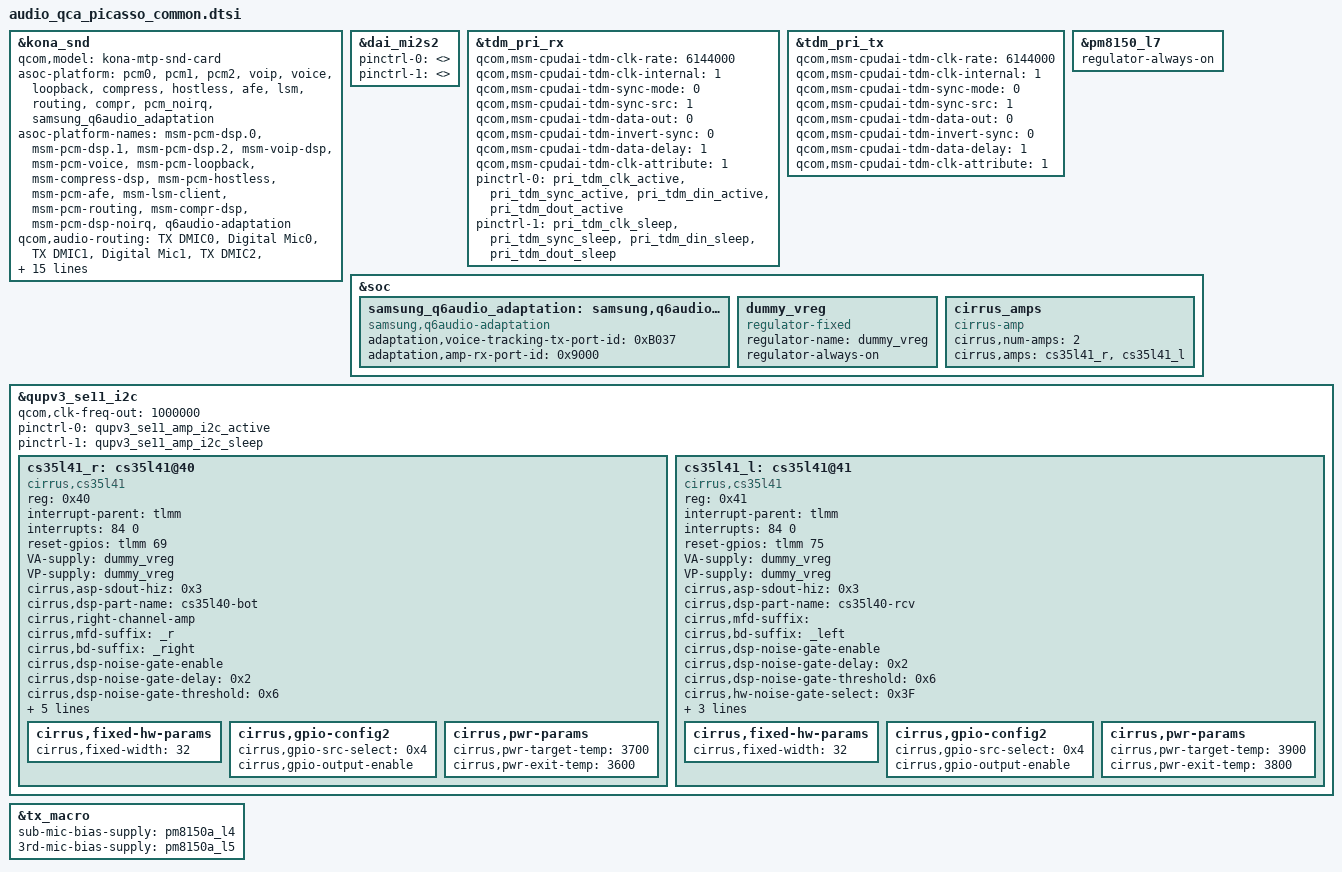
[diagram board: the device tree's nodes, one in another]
/* Copyright (c) 2018, The Linux Foundation. All rights reserved.
 *
 * This program is free software; you can redistribute it and/or modify
 * it under the terms of the GNU General Public License version 2 and
 * only version 2 as published by the Free Software Foundation.
 *
 * This program is distributed in the hope that it will be useful,
 * but WITHOUT ANY WARRANTY; without even the implied warranty of
 * MERCHANTABILITY or FITNESS FOR A PARTICULAR PURPOSE.  See the
 * GNU General Public License for more details.
 */

&kona_snd {
	qcom,model = "kona-mtp-snd-card";

	asoc-platform = <&pcm0>, <&pcm1>, <&pcm2>, <&voip>, <&voice>,
		<&loopback>, <&compress>, <&hostless>,
		<&afe>, <&lsm>, <&routing>, <&compr>,
		<&pcm_noirq>, <&samsung_q6audio_adaptation>;
	asoc-platform-names = "msm-pcm-dsp.0", "msm-pcm-dsp.1",
		"msm-pcm-dsp.2", "msm-voip-dsp",
		"msm-pcm-voice", "msm-pcm-loopback",
		"msm-compress-dsp", "msm-pcm-hostless",
		"msm-pcm-afe", "msm-lsm-client",
		"msm-pcm-routing", "msm-compr-dsp",
		"msm-pcm-dsp-noirq", "q6audio-adaptation";
	qcom,audio-routing =
		"TX DMIC0", "Digital Mic0",
		"TX DMIC1", "Digital Mic1",
		"TX DMIC2", "MIC BIAS External1",
		"MIC BIAS External1", "Digital Mic2",
		"TX DMIC3", "Digital Mic3",
		"TX DMIC4", "MIC BIAS External2",
		"MIC BIAS External2", "Digital Mic4",
		"TX DMIC5", "Digital Mic5",
		"VA DMIC0", "Digital Mic0",
		"VA DMIC1", "Digital Mic1",
		"VA DMIC2", "Digital Mic2",
		"VA DMIC3", "Digital Mic3",
		"VA DMIC4", "Digital Mic4",
		"VA DMIC5", "Digital Mic5",
		"L SPK", "Left AMP SPK",
		"R SPK", "Right AMP SPK";
	qcom,msm-mbhc-hphl-swh = <0>;
	qcom,msm-mbhc-gnd-swh = <0>;
	qcom,wsa-max-devs = <0>;
	qcom,codec-max-aux-devs = <0>;
	fsa4480-i2c-handle = <>;
};

&dai_mi2s2 {
	pinctrl-0 = <>;
	pinctrl-1 = <>;
};

&tdm_pri_rx {
	qcom,msm-cpudai-tdm-clk-rate = <6144000>;
	qcom,msm-cpudai-tdm-clk-internal = <1>;
	qcom,msm-cpudai-tdm-sync-mode = <0>;
	qcom,msm-cpudai-tdm-sync-src = <1>;
	qcom,msm-cpudai-tdm-data-out = <0>;
	qcom,msm-cpudai-tdm-invert-sync = <0>;
	qcom,msm-cpudai-tdm-data-delay = <1>;
	qcom,msm-cpudai-tdm-clk-attribute = /bits/ 16 <1>;

	pinctrl-names = "default", "sleep";
	pinctrl-0 = <&pri_tdm_clk_active &pri_tdm_sync_active
		    &pri_tdm_din_active &pri_tdm_dout_active>;
	pinctrl-1 = <&pri_tdm_clk_sleep &pri_tdm_sync_sleep
			&pri_tdm_din_sleep &pri_tdm_dout_sleep>;
};
&tdm_pri_tx {
	qcom,msm-cpudai-tdm-clk-rate = <6144000>;
	qcom,msm-cpudai-tdm-clk-internal = <1>;
	qcom,msm-cpudai-tdm-sync-mode = <0>;
	qcom,msm-cpudai-tdm-sync-src = <1>;
	qcom,msm-cpudai-tdm-data-out = <0>;
	qcom,msm-cpudai-tdm-invert-sync = <0>;
	qcom,msm-cpudai-tdm-data-delay = <1>;
	qcom,msm-cpudai-tdm-clk-attribute = /bits/ 16 <1>;
};

&pm8150_l7 {
	regulator-always-on;
};

&soc {
	samsung_q6audio_adaptation: samsung,q6audio-adaptation {
		compatible = "samsung,q6audio-adaptation";
		adaptation,voice-tracking-tx-port-id = <0xB037>;
		adaptation,amp-rx-port-id = <0x9000>;
	};

	dummy_vreg: dummy_vreg {
		compatible = "regulator-fixed";
		status = "ok";
		regulator-name = "dummy_vreg";
		regulator-always-on;
	};

	cirrus_amps {
		compatible = "cirrus-amp";
		cirrus,num-amps = <2>;
		cirrus,amps = <&cs35l41_r &cs35l41_l>;
	};
};


&qupv3_se11_i2c {
	qcom,clk-freq-out = <1000000>;
	status = "ok";
	pinctrl-0 = <&qupv3_se11_amp_i2c_active>;
	pinctrl-1 = <&qupv3_se11_amp_i2c_sleep>;

	cs35l41_r: cs35l41@40 {
		#sound-dai-cells = <1>;
		compatible = "cirrus,cs35l41";
		reg = <0x40>;
		interrupt-parent = <&tlmm>;
		interrupts = <84 0>;
		reset-gpios = <&tlmm 69 0>;
		VA-supply = <&dummy_vreg>;
		VP-supply = <&dummy_vreg>;
		cirrus,asp-sdout-hiz = <0x3>;

		cirrus,dsp-part-name = "cs35l40-bot";
		cirrus,right-channel-amp;
		cirrus,mfd-suffix = "_r";
		cirrus,bd-suffix = "_right";

		cirrus,dsp-noise-gate-enable;
		cirrus,dsp-noise-gate-delay = <0x2>;
		cirrus,dsp-noise-gate-threshold = <0x6>;

		cirrus,hw-noise-gate-select = <0x3F>;
		cirrus,hw-noise-gate-delay = <0x2>;
		cirrus,hw-noise-gate-threshold = <0x6>;
		cirrus,boost-peak-milliamp = <4100>;

		pinctrl-names = "default";
		pinctrl-0 = <&cs35l41_gpio_active>;

		cirrus,fixed-hw-params	{
			cirrus,fixed-width = <32>;
		};

		cirrus,gpio-config2 {
			cirrus,gpio-src-select = <0x4>;
			cirrus,gpio-output-enable;
		};

		cirrus,pwr-params {
			cirrus,pwr-target-temp = <3700>;
			cirrus,pwr-exit-temp = <3600>;
		};
	};

	cs35l41_l: cs35l41@41 {
		#sound-dai-cells = <1>;
		compatible = "cirrus,cs35l41";
		reg = <0x41>;
		interrupt-parent = <&tlmm>;
		interrupts = <84 0>;
		reset-gpios = <&tlmm 75 0>;
		VA-supply = <&dummy_vreg>;
		VP-supply = <&dummy_vreg>;
		cirrus,asp-sdout-hiz = <0x3>;

		cirrus,dsp-part-name = "cs35l40-rcv";
		cirrus,mfd-suffix = "";
		cirrus,bd-suffix = "_left";

		cirrus,dsp-noise-gate-enable;
		cirrus,dsp-noise-gate-delay = <0x2>;
		cirrus,dsp-noise-gate-threshold = <0x6>;

		cirrus,hw-noise-gate-select = <0x3F>;
		cirrus,hw-noise-gate-delay = <0x2>;
		cirrus,hw-noise-gate-threshold = <0x6>;
		cirrus,boost-peak-milliamp = <4100>;

		cirrus,fixed-hw-params	{
			cirrus,fixed-width = <32>;
		};

		cirrus,gpio-config2 {
			cirrus,gpio-src-select = <0x4>;
			cirrus,gpio-output-enable;
		};

		cirrus,pwr-params {
			cirrus,pwr-target-temp = <3900>;
			cirrus,pwr-exit-temp = <3800>;
		};
	};
};

&tx_macro {
	sub-mic-bias-supply = <&pm8150a_l4>;
	3rd-mic-bias-supply = <&pm8150a_l5>;
};
